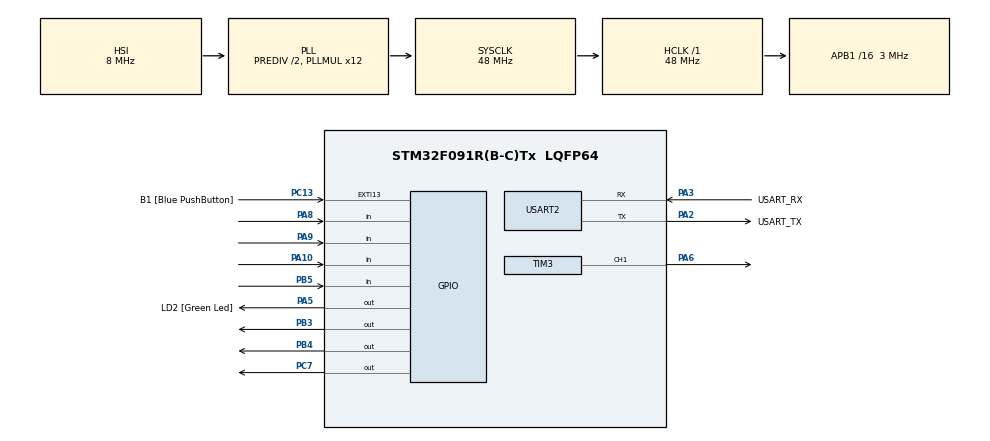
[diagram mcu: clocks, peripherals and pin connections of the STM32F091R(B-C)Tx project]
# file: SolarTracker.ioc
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Mcu.Family=STM32F0
Mcu.Name=STM32F091R(B-C)Tx
Mcu.Package=LQFP64
PA10.Signal=GPIO_Input
PA13.GPIO_Label=TMS
PA13.Mode=Serial_Wire
PA13.Signal=SYS_SWDIO
PA14.GPIO_Label=TCK
PA14.Mode=Serial_Wire
PA14.Signal=SYS_SWCLK
PA2.GPIO_Label=USART_TX
PA2.GPIO_Mode=GPIO_MODE_AF_PP
PA2.GPIO_PuPd=GPIO_NOPULL
PA2.GPIO_Speed=GPIO_SPEED_FREQ_LOW
PA2.Mode=Asynchronous
PA2.Signal=USART2_TX
PA3.GPIO_Label=USART_RX
PA3.GPIO_Mode=GPIO_MODE_AF_PP
PA3.GPIO_PuPd=GPIO_NOPULL
PA3.GPIO_Speed=GPIO_SPEED_FREQ_LOW
PA3.Mode=Asynchronous
PA3.Signal=USART2_RX
PA5.GPIO_Label=LD2 [Green Led]
PA5.GPIO_Mode=GPIO_MODE_OUTPUT_PP
PA5.GPIO_PuPd=GPIO_NOPULL
PA5.GPIO_Speed=GPIO_SPEED_FREQ_LOW
PA5.Signal=GPIO_Output
PA6.Signal=S_TIM3_CH1
PA8.Signal=GPIO_Input
PA9.Signal=GPIO_Input
PB3.Signal=GPIO_Output
PB4.Signal=GPIO_Output
PB5.Signal=GPIO_Input
PC13.GPIO_Label=B1 [Blue PushButton]
PC13.GPIO_ModeDefaultEXTI=GPIO_MODE_IT_FALLING
PC13.Signal=GPXTI13
PC14OSC32_IN.Mode=LSE-External-Oscillator
PC14OSC32_IN.Signal=RCC_OSC32_IN
PC15OSC32_OUT.Mode=LSE-External-Oscillator
PC15OSC32_OUT.Signal=RCC_OSC32_OUT
PC7.Signal=GPIO_Output
PF0-OSC_IN.Mode=HSE-External-Clock-Source
PF0-OSC_IN.Signal=RCC_OSC_IN
PF1-OSC_OUT.Signal=RCC_OSC_OUT
ProjectManager.HeapSize=0x200
ProjectManager.StackSize=0x400
ProjectManager.TargetToolchain=STM32CubeIDE
RCC.AHBFreq_Value=48000000
RCC.APB1CLKDivider=RCC_HCLK_DIV16
RCC.APB1Freq_Value=3000000
RCC.APB1TimFreq_Value=6000000
RCC.FLatency-AdvancedSettings=FLASH_LATENCY_1
RCC.HCLKFreq_Value=48000000
RCC.PLLDivider=RCC_PREDIV_DIV2
RCC.PLLMUL=RCC_PLL_MUL12
RCC.PREFETCH_ENABLE-AdvancedSettings=1
RCC.SYSCLKFreq_VALUE=48000000
RCC.SYSCLKSource=RCC_SYSCLKSOURCE_PLLCLK
SH.S_TIM3_CH1.0=TIM3_CH1,PWM Generation1 CH1
TIM3.AutoReloadPreload=TIM_AUTORELOAD_PRELOAD_ENABLE
TIM3.Channel-PWM\ Generation1\ CH1=TIM_CHANNEL_1
TIM3.ClockDivision=TIM_CLOCKDIVISION_DIV1
TIM3.Period=255
TIM3.Prescaler=22
TIM3.Pulse-PWM\ Generation1\ CH1=128
USART2.VirtualMode=VM_ASYNC
USART2.VirtualMode-Asynchronous=VM_ASYNC
VP_TIM3_VS_ClockSourceINT.Mode=Internal
board=NUCLEO-F091RC

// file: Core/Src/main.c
/* USER CODE BEGIN Header */
/**
  ******************************************************************************
  * @file           : main.c
  * @brief          : Main program body
  ******************************************************************************
  * @attention
  *
  * Copyright (c) 2023 STMicroelectronics.
  * All rights reserved.
  *
  * This software is licensed under terms that can be found in the LICENSE file
  * in the root directory of this software component.
  * If no LICENSE file comes with this software, it is provided AS-IS.
  *
  ******************************************************************************
  */
/* USER CODE END Header */
#include "main.h"

TIM_HandleTypeDef htim3;

UART_HandleTypeDef huart2;

/* USER CODE BEGIN PV */

  TIM_OC_InitTypeDef sConfigOC = {0};
/* USER CODE END PV */

void SystemClock_Config(void);
static void MX_GPIO_Init(void);
static void MX_USART2_UART_Init(void);
static void MX_TIM3_Init(void);

/* USER CODE BEGIN 0 */
void dutyCycle(uint32_t p)
{

	TIM3->CCR1 = p;
	HAL_TIM_PWM_Start(&htim3, TIM_CHANNEL_1);
}
uint8_t ucDebug_PWM_value =128;
/* USER CODE END 0 */

int main(void)
{

  /* MCU Configuration--------------------------------------------------------*/

  /* Reset of all peripherals, Initializes the Flash interface and the Systick. */
  HAL_Init();

  /* Configure the system clock */
  SystemClock_Config();

  /* Initialize all configured peripherals */
  MX_GPIO_Init();
  MX_USART2_UART_Init();
  MX_TIM3_Init();
  /* USER CODE BEGIN 2 */
  TIM3->CCR1 = 30;
  HAL_TIM_PWM_Start(&htim3, TIM_CHANNEL_1);

  /// uint32_t pwmData[10] = {10, 20, 30, 40, 50, 60, 70, 80, 90, 100};
  /// HAL_TIM_PWM_Start_DMA(&htim3, TIM_CHANNEL_1, (uint32_t *)pwmData, 10);
  /* USER CODE END 2 */

  /* Infinite loop */
  /* USER CODE BEGIN WHILE */
  while (1)
  {
	  uint32_t i = 1;

	  dutyCycle(ucDebug_PWM_value);

	  /*for(i = 1; i < 255; i++)
	  {
		  dutyCycle(i);
		  HAL_Delay(10);
	  }*/
    /* USER CODE END WHILE */

  }
}

void SystemClock_Config(void)
{
  RCC_OscInitTypeDef RCC_OscInitStruct = {0};
  RCC_ClkInitTypeDef RCC_ClkInitStruct = {0};
  RCC_PeriphCLKInitTypeDef PeriphClkInit = {0};

  /** Initializes the RCC Oscillators according to the specified parameters
  * in the RCC_OscInitTypeDef structure.
  */
  RCC_OscInitStruct.OscillatorType = RCC_OSCILLATORTYPE_HSI;
  RCC_OscInitStruct.HSIState = RCC_HSI_ON;
  RCC_OscInitStruct.HSICalibrationValue = RCC_HSICALIBRATION_DEFAULT;
  RCC_OscInitStruct.PLL.PLLState = RCC_PLL_ON;
  RCC_OscInitStruct.PLL.PLLSource = RCC_PLLSOURCE_HSI;
  RCC_OscInitStruct.PLL.PLLMUL = RCC_PLL_MUL12;
  RCC_OscInitStruct.PLL.PREDIV = RCC_PREDIV_DIV2;
  if (HAL_RCC_OscConfig(&RCC_OscInitStruct) != HAL_OK)
  {
    Error_Handler();
  }

  /** Initializes the CPU, AHB and APB buses clocks
  */
  RCC_ClkInitStruct.ClockType = RCC_CLOCKTYPE_HCLK|RCC_CLOCKTYPE_SYSCLK
                              |RCC_CLOCKTYPE_PCLK1;
  RCC_ClkInitStruct.SYSCLKSource = RCC_SYSCLKSOURCE_PLLCLK;
  RCC_ClkInitStruct.AHBCLKDivider = RCC_SYSCLK_DIV1;
  RCC_ClkInitStruct.APB1CLKDivider = RCC_HCLK_DIV16;

  if (HAL_RCC_ClockConfig(&RCC_ClkInitStruct, FLASH_LATENCY_1) != HAL_OK)
  {
    Error_Handler();
  }
  PeriphClkInit.PeriphClockSelection = RCC_PERIPHCLK_USART2;
  PeriphClkInit.Usart2ClockSelection = RCC_USART2CLKSOURCE_PCLK1;
  if (HAL_RCCEx_PeriphCLKConfig(&PeriphClkInit) != HAL_OK)
  {
    Error_Handler();
  }
}

static void MX_TIM3_Init(void)
{

  TIM_ClockConfigTypeDef sClockSourceConfig = {0};
  TIM_MasterConfigTypeDef sMasterConfig = {0};
  TIM_OC_InitTypeDef sConfigOC = {0};

  htim3.Instance = TIM3;
  htim3.Init.Prescaler = 22;
  htim3.Init.CounterMode = TIM_COUNTERMODE_UP;
  htim3.Init.Period = 255;
  htim3.Init.ClockDivision = TIM_CLOCKDIVISION_DIV1;
  htim3.Init.AutoReloadPreload = TIM_AUTORELOAD_PRELOAD_ENABLE;
  if (HAL_TIM_Base_Init(&htim3) != HAL_OK)
  {
    Error_Handler();
  }
  sClockSourceConfig.ClockSource = TIM_CLOCKSOURCE_INTERNAL;
  if (HAL_TIM_ConfigClockSource(&htim3, &sClockSourceConfig) != HAL_OK)
  {
    Error_Handler();
  }
  if (HAL_TIM_PWM_Init(&htim3) != HAL_OK)
  {
    Error_Handler();
  }
  sMasterConfig.MasterOutputTrigger = TIM_TRGO_RESET;
  sMasterConfig.MasterSlaveMode = TIM_MASTERSLAVEMODE_DISABLE;
  if (HAL_TIMEx_MasterConfigSynchronization(&htim3, &sMasterConfig) != HAL_OK)
  {
    Error_Handler();
  }
  sConfigOC.OCMode = TIM_OCMODE_PWM1;
  sConfigOC.Pulse = 128;
  sConfigOC.OCPolarity = TIM_OCPOLARITY_HIGH;
  sConfigOC.OCFastMode = TIM_OCFAST_DISABLE;
  if (HAL_TIM_PWM_ConfigChannel(&htim3, &sConfigOC, TIM_CHANNEL_1) != HAL_OK)
  {
    Error_Handler();
  }
  HAL_TIM_MspPostInit(&htim3);

}

static void MX_USART2_UART_Init(void)
{

  huart2.Instance = USART2;
  huart2.Init.BaudRate = 115200;
  huart2.Init.WordLength = UART_WORDLENGTH_8B;
  huart2.Init.StopBits = UART_STOPBITS_1;
  huart2.Init.Parity = UART_PARITY_NONE;
  huart2.Init.Mode = UART_MODE_TX_RX;
  huart2.Init.HwFlowCtl = UART_HWCONTROL_NONE;
  huart2.Init.OverSampling = UART_OVERSAMPLING_16;
  huart2.Init.OneBitSampling = UART_ONE_BIT_SAMPLE_DISABLE;
  huart2.AdvancedInit.AdvFeatureInit = UART_ADVFEATURE_NO_INIT;
  if (HAL_UART_Init(&huart2) != HAL_OK)
  {
    Error_Handler();
  }

}

static void MX_GPIO_Init(void)
{
  GPIO_InitTypeDef GPIO_InitStruct = {0};

  /* GPIO Ports Clock Enable */
  __HAL_RCC_GPIOC_CLK_ENABLE();
  __HAL_RCC_GPIOF_CLK_ENABLE();
  __HAL_RCC_GPIOA_CLK_ENABLE();
  __HAL_RCC_GPIOB_CLK_ENABLE();

  /*Configure GPIO pin Output Level */
  HAL_GPIO_WritePin(LD2_GPIO_Port, LD2_Pin, GPIO_PIN_RESET);

  /*Configure GPIO pin Output Level */
  HAL_GPIO_WritePin(GPIOC, GPIO_PIN_7, GPIO_PIN_RESET);

  /*Configure GPIO pin Output Level */
  HAL_GPIO_WritePin(GPIOB, GPIO_PIN_3|GPIO_PIN_4, GPIO_PIN_RESET);

  /*Configure GPIO pin : B1_Pin */
  GPIO_InitStruct.Pin = B1_Pin;
  GPIO_InitStruct.Mode = GPIO_MODE_IT_FALLING;
  GPIO_InitStruct.Pull = GPIO_NOPULL;
  HAL_GPIO_Init(B1_GPIO_Port, &GPIO_InitStruct);

  /*Configure GPIO pin : LD2_Pin */
  GPIO_InitStruct.Pin = LD2_Pin;
  GPIO_InitStruct.Mode = GPIO_MODE_OUTPUT_PP;
  GPIO_InitStruct.Pull = GPIO_NOPULL;
  GPIO_InitStruct.Speed = GPIO_SPEED_FREQ_LOW;
  HAL_GPIO_Init(LD2_GPIO_Port, &GPIO_InitStruct);

  /*Configure GPIO pin : PC7 */
  GPIO_InitStruct.Pin = GPIO_PIN_7;
  GPIO_InitStruct.Mode = GPIO_MODE_OUTPUT_PP;
  GPIO_InitStruct.Pull = GPIO_NOPULL;
  GPIO_InitStruct.Speed = GPIO_SPEED_FREQ_LOW;
  HAL_GPIO_Init(GPIOC, &GPIO_InitStruct);

  /*Configure GPIO pins : PA8 PA9 PA10 */
  GPIO_InitStruct.Pin = GPIO_PIN_8|GPIO_PIN_9|GPIO_PIN_10;
  GPIO_InitStruct.Mode = GPIO_MODE_INPUT;
  GPIO_InitStruct.Pull = GPIO_NOPULL;
  HAL_GPIO_Init(GPIOA, &GPIO_InitStruct);

  /*Configure GPIO pins : PB3 PB4 */
  GPIO_InitStruct.Pin = GPIO_PIN_3|GPIO_PIN_4;
  GPIO_InitStruct.Mode = GPIO_MODE_OUTPUT_PP;
  GPIO_InitStruct.Pull = GPIO_NOPULL;
  GPIO_InitStruct.Speed = GPIO_SPEED_FREQ_LOW;
  HAL_GPIO_Init(GPIOB, &GPIO_InitStruct);

  /*Configure GPIO pin : PB5 */
  GPIO_InitStruct.Pin = GPIO_PIN_5;
  GPIO_InitStruct.Mode = GPIO_MODE_INPUT;
  GPIO_InitStruct.Pull = GPIO_NOPULL;
  HAL_GPIO_Init(GPIOB, &GPIO_InitStruct);

}

void Error_Handler(void)
{
  __disable_irq();
  while (1)
  {
  }
}
